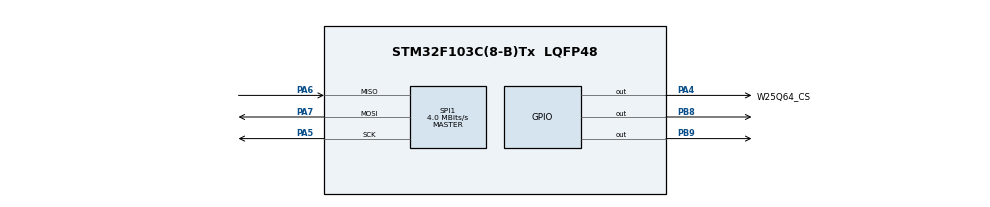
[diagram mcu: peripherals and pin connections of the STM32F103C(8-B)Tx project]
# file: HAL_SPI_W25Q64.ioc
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Mcu.Family=STM32F1
Mcu.Name=STM32F103C(8-B)Tx
Mcu.Package=LQFP48
NVIC.PriorityGroup=NVIC_PRIORITYGROUP_4
PA13.Mode=Serial_Wire
PA13.Signal=SYS_JTMS-SWDIO
PA14.Mode=Serial_Wire
PA14.Signal=SYS_JTCK-SWCLK
PA4.GPIO_Label=W25Q64_CS
PA4.PinState=GPIO_PIN_SET
PA4.Signal=GPIO_Output
PA5.Mode=Full_Duplex_Master
PA5.Signal=SPI1_SCK
PA6.Mode=Full_Duplex_Master
PA6.Signal=SPI1_MISO
PA7.Mode=Full_Duplex_Master
PA7.Signal=SPI1_MOSI
PB8.GPIO_ModeDefaultOutputPP=GPIO_MODE_OUTPUT_OD
PB8.GPIO_PuPd=GPIO_NOPULL
PB8.GPIO_Speed=GPIO_SPEED_FREQ_HIGH
PB8.PinState=GPIO_PIN_SET
PB8.Signal=GPIO_Output
PB9.GPIO_ModeDefaultOutputPP=GPIO_MODE_OUTPUT_OD
PB9.GPIO_PuPd=GPIO_NOPULL
PB9.GPIO_Speed=GPIO_SPEED_FREQ_HIGH
PB9.PinState=GPIO_PIN_SET
PB9.Signal=GPIO_Output
ProjectManager.HeapSize=0x200
ProjectManager.StackSize=0x400
ProjectManager.TargetToolchain=MDK-ARM V5.32
RCC.APB1Freq_Value=8000000
RCC.APB2Freq_Value=8000000
SPI1.CalculateBaudRate=4.0 MBits/s
SPI1.Direction=SPI_DIRECTION_2LINES
SPI1.Mode=SPI_MODE_MASTER
SPI1.VirtualType=VM_MASTER
board=custom

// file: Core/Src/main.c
/* USER CODE BEGIN Header */
/**
  ******************************************************************************
  * @file           : main.c
  * @brief          : Main program body
  ******************************************************************************
  * @attention
  *
  * Copyright (c) 2026 STMicroelectronics.
  * All rights reserved.
  *
  * This software is licensed under terms that can be found in the LICENSE file
  * in the root directory of this software component.
  * If no LICENSE file comes with this software, it is provided AS-IS.
  *
  ******************************************************************************
  */
/* USER CODE END Header */
#include "main.h"
#include "spi.h"
#include "gpio.h"

/* USER CODE BEGIN Includes */
#include "OLED.h"
#include "W25Q64.h"
/* USER CODE END Includes */

void SystemClock_Config(void);

int main(void)
{

  /* MCU Configuration--------------------------------------------------------*/

  /* Reset of all peripherals, Initializes the Flash interface and the Systick. */
  HAL_Init();

  /* Configure the system clock */
  SystemClock_Config();

  /* Initialize all configured peripherals */
  MX_GPIO_Init();
  MX_SPI1_Init();
  /* USER CODE BEGIN 2 */
  OLED_Init();
  OLED_ShowString(1, 1, "ID:");
  OLED_ShowString(2, 1, "Reg1:");

	uint8_t ID[3];
	uint8_t RegData;
	W25Q64_ReadID(ID);
	W25Q64_WriteEnable();

	W25Q64_ReadReg(&RegData);

	OLED_ShowHexNum(1,4,ID[0],2);
	OLED_ShowHexNum(1,7,ID[1],2);
	OLED_ShowHexNum(1,10,ID[2],2);

	OLED_ShowHexNum(2,6,RegData,2);

  /* USER CODE END 2 */

  /* Infinite loop */
  while (1)
  {

  }
}

void SystemClock_Config(void)
{
  RCC_OscInitTypeDef RCC_OscInitStruct = {0};
  RCC_ClkInitTypeDef RCC_ClkInitStruct = {0};

  /** Initializes the RCC Oscillators according to the specified parameters
  * in the RCC_OscInitTypeDef structure.
  */
  RCC_OscInitStruct.OscillatorType = RCC_OSCILLATORTYPE_HSI;
  RCC_OscInitStruct.HSIState = RCC_HSI_ON;
  RCC_OscInitStruct.HSICalibrationValue = RCC_HSICALIBRATION_DEFAULT;
  RCC_OscInitStruct.PLL.PLLState = RCC_PLL_NONE;
  if (HAL_RCC_OscConfig(&RCC_OscInitStruct) != HAL_OK)
  {
    Error_Handler();
  }

  /** Initializes the CPU, AHB and APB buses clocks
  */
  RCC_ClkInitStruct.ClockType = RCC_CLOCKTYPE_HCLK|RCC_CLOCKTYPE_SYSCLK
                              |RCC_CLOCKTYPE_PCLK1|RCC_CLOCKTYPE_PCLK2;
  RCC_ClkInitStruct.SYSCLKSource = RCC_SYSCLKSOURCE_HSI;
  RCC_ClkInitStruct.AHBCLKDivider = RCC_SYSCLK_DIV1;
  RCC_ClkInitStruct.APB1CLKDivider = RCC_HCLK_DIV1;
  RCC_ClkInitStruct.APB2CLKDivider = RCC_HCLK_DIV1;

  if (HAL_RCC_ClockConfig(&RCC_ClkInitStruct, FLASH_LATENCY_0) != HAL_OK)
  {
    Error_Handler();
  }
}

void Error_Handler(void)
{
  __disable_irq();
  while (1)
  {
  }
}
